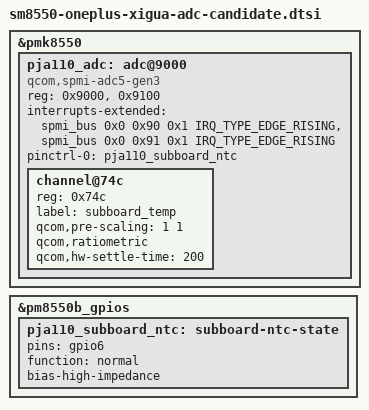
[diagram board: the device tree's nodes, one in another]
// SPDX-License-Identifier: BSD-3-Clause
/* Offline candidate: upstream ADC5 Gen3 plus factory 22851 subboard NTC. */
&pmk8550 {
	pja110_adc: adc@9000 {
		compatible = "qcom,spmi-adc5-gen3";
		reg = <0x9000>, <0x9100>;
		interrupts-extended = <&spmi_bus 0x0 0x90 0x1 IRQ_TYPE_EDGE_RISING>,
				      <&spmi_bus 0x0 0x91 0x1 IRQ_TYPE_EDGE_RISING>;
		#address-cells = <1>;
		#size-cells = <0>;
		#io-channel-cells = <1>;
		pinctrl-names = "default";
		pinctrl-0 = <&pja110_subboard_ntc>;

		channel@74c {
			/* PM8550B SID 7, AMUX3 GPIO6, 100k pull-up. */
			reg = <0x74c>;
			label = "subboard_temp";
			qcom,pre-scaling = <1 1>;
			qcom,ratiometric;
			qcom,hw-settle-time = <200>;
		};
	};
};

&pm8550b_gpios {
	pja110_subboard_ntc: subboard-ntc-state {
		pins = "gpio6";
		function = "normal";
		bias-high-impedance;
	};
};
